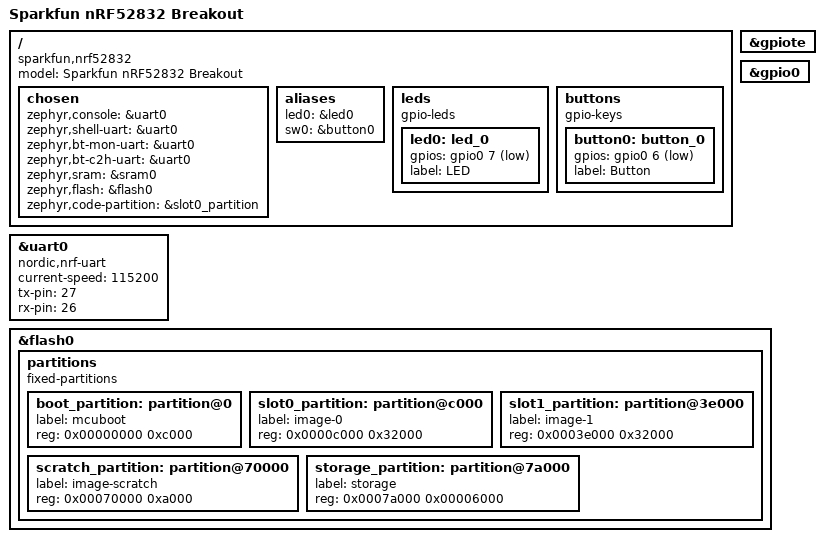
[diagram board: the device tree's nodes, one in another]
/*
 * Copyright (c) 2017 Shawn Nock <shawn@monadnock.ca>
 * Copyright (c) 2017 Linaro Limited
 *
 * SPDX-License-Identifier: Apache-2.0
 */

/dts-v1/;
#include <nordic/nrf52832_qfaa.dtsi>

/ {
	model = "Sparkfun nRF52832 Breakout";
	compatible = "sparkfun,nrf52832";

	chosen {
		zephyr,console = &uart0;
		zephyr,shell-uart = &uart0;
		zephyr,bt-mon-uart = &uart0;
		zephyr,bt-c2h-uart = &uart0;
		zephyr,sram = &sram0;
		zephyr,flash = &flash0;
		zephyr,code-partition = &slot0_partition;
	};

	/* These aliases are provided for compatibility with samples */
	aliases {
		led0 = &led0;
		sw0 = &button0;
	};

	leds {
		compatible = "gpio-leds";
		led0: led_0 {
			gpios = <&gpio0 7 GPIO_ACTIVE_LOW>;
			label = "LED";
		};
	};

	buttons {
		compatible = "gpio-keys";
		button0: button_0 {
			/* gpio flags need validation */
			gpios = <&gpio0 6 (GPIO_PULL_UP | GPIO_ACTIVE_LOW)>;
			label = "Button";
		};
	};
};

&gpiote {
	status = "okay";
};

&gpio0 {
	status = "okay";
};

&uart0 {
	compatible = "nordic,nrf-uart";
	current-speed = <115200>;
	status = "okay";
	tx-pin = <27>;
	rx-pin = <26>;
};

&flash0 {
	/*
	 * For more information, see:
	 * https://docs.zephyrproject.org/latest/guides/dts/legacy-macros.html#legacy-flash-partitions
	 */
	partitions {
		compatible = "fixed-partitions";
		#address-cells = <1>;
		#size-cells = <1>;

		boot_partition: partition@0 {
			label = "mcuboot";
			reg = <0x00000000 0xc000>;
		};
		slot0_partition: partition@c000 {
			label = "image-0";
			reg = <0x0000c000 0x32000>;
		};
		slot1_partition: partition@3e000 {
			label = "image-1";
			reg = <0x0003e000 0x32000>;
		};
		scratch_partition: partition@70000 {
			label = "image-scratch";
			reg = <0x00070000 0xa000>;
		};
		storage_partition: partition@7a000 {
			label = "storage";
			reg = <0x0007a000 0x00006000>;
		};
	};
};
